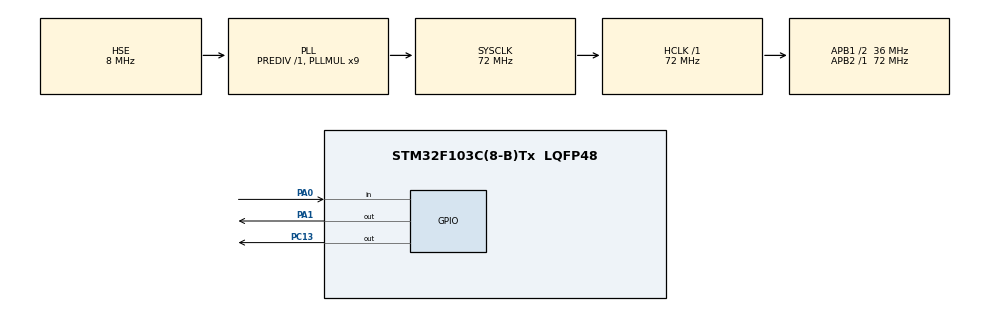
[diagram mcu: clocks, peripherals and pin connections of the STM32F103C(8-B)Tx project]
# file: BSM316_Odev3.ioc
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Mcu.Family=STM32F1
Mcu.Name=STM32F103C(8-B)Tx
Mcu.Package=LQFP48
NVIC.PriorityGroup=NVIC_PRIORITYGROUP_4
NVIC.TIM2_IRQn=true\:0\:0\:false\:false\:true\:true\:true\:true
PA0-WKUP.GPIO_PuPd=GPIO_PULLUP
PA0-WKUP.Signal=GPIO_Input
PA1.Signal=GPIO_Output
PA13.Mode=Serial_Wire
PA13.Signal=SYS_JTMS-SWDIO
PA14.Mode=Serial_Wire
PA14.Signal=SYS_JTCK-SWCLK
PC13-TAMPER-RTC.Signal=GPIO_Output
PD0-OSC_IN.Mode=HSE-External-Oscillator
PD0-OSC_IN.Signal=RCC_OSC_IN
PD1-OSC_OUT.Mode=HSE-External-Oscillator
PD1-OSC_OUT.Signal=RCC_OSC_OUT
ProjectManager.HeapSize=0x200
ProjectManager.StackSize=0x400
ProjectManager.TargetToolchain=Makefile
RCC.AHBFreq_Value=72000000
RCC.APB1CLKDivider=RCC_HCLK_DIV2
RCC.APB1Freq_Value=36000000
RCC.APB1TimFreq_Value=72000000
RCC.APB2Freq_Value=72000000
RCC.APB2TimFreq_Value=72000000
RCC.HCLKFreq_Value=72000000
RCC.PLLMUL=RCC_PLL_MUL9
RCC.PLLSourceVirtual=RCC_PLLSOURCE_HSE
RCC.SYSCLKFreq_VALUE=72000000
RCC.SYSCLKSource=RCC_SYSCLKSOURCE_PLLCLK
RCC.USBFreq_Value=72000000
TIM2.Period=9999
TIM2.Prescaler=7199
VP_TIM2_VS_ClockSourceINT.Mode=Internal
board=custom

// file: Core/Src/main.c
/* USER CODE BEGIN Header */
/**
  ******************************************************************************
  * @file           : main.c
  * @brief          : Main program body
  ******************************************************************************
  * @attention
  *
  * Copyright (c) 2026 STMicroelectronics.
  * All rights reserved.
  *
  * This software is licensed under terms that can be found in the LICENSE file
  * in the root directory of this software component.
  * If no LICENSE file comes with this software, it is provided AS-IS.
  *
  ******************************************************************************
  */
/* USER CODE END Header */
#include "main.h"

TIM_HandleTypeDef htim2;

void SystemClock_Config(void);
static void MX_GPIO_Init(void);
static void MX_TIM2_Init(void);

/* USER CODE BEGIN 0 */
#define FLASH_USER_ADDR 0x0800FC00 // STM32F103C8T6 için 63. sayfa başlangıç adresi

uint32_t blink_count = 4;
uint32_t current_blink = 0;
uint8_t is_waiting = 0;
uint8_t wait_seconds = 0;
uint8_t led_state = 0; // 0: Sönük, 1: Yanıyor

void Save_Blink_Count_To_Flash(uint16_t data) {
    HAL_FLASH_Unlock();

    FLASH_EraseInitTypeDef eraseConfig;
    uint32_t PageError = 0;
    eraseConfig.TypeErase = FLASH_TYPEERASE_PAGES;
    eraseConfig.PageAddress = FLASH_USER_ADDR;
    eraseConfig.NbPages = 1;

    HAL_FLASHEx_Erase(&eraseConfig, &PageError); // Sayfayı sil
    HAL_FLASH_Program(FLASH_TYPEPROGRAM_HALFWORD, FLASH_USER_ADDR, data); // Yeni değeri yaz

    HAL_FLASH_Lock();
}

uint16_t Read_Blink_Count_From_Flash(void) {
    return *(__IO uint16_t *)FLASH_USER_ADDR; // Belirtilen adresten değeri oku
}

/* USER CODE END 0 */

int main(void)
{

  /* MCU Configuration--------------------------------------------------------*/

  /* Reset of all peripherals, Initializes the Flash interface and the Systick. */
  HAL_Init();

  /* Configure the system clock */
  SystemClock_Config();

  /* Initialize all configured peripherals */
  MX_GPIO_Init();
  MX_TIM2_Init();
  /* USER CODE BEGIN 2 */

  HAL_GPIO_WritePin(GPIOA, GPIO_PIN_1, GPIO_PIN_RESET); // PA1 sürekli lojik 0 olarak ayarlandı
  HAL_GPIO_WritePin(GPIOC, GPIO_PIN_13, GPIO_PIN_SET); // LED başlangıçta sönük

  uint16_t read_val = Read_Blink_Count_From_Flash();

  // Flash boş ise (0xFFFF) veya değer 7'den büyükse
  if (read_val > 7 || read_val < 4) {
      blink_count = 4;
      Save_Blink_Count_To_Flash((uint16_t)blink_count);
  } else {
      blink_count = read_val; // Değer geçerliyse flash'tan yükle
  }

  HAL_TIM_Base_Start_IT(&htim2); // TIM2 kesmelerini başlat
  /* USER CODE END 2 */

  /* Infinite loop */
  while (1)
  {

    /* USER CODE BEGIN 3 */

    static uint32_t btn_press_time = 0;
  static uint8_t btn_state = 0; // 0: Basılmadı, 1: Basıldı, 2: Uzun basıldı (bekleme)

  // PA0'ın düşük olması (lojik 0), butonun basıldığını (veya PA0 ile PA1'in kısa devre edildiğini) gösterir
  if (HAL_GPIO_ReadPin(GPIOA, GPIO_PIN_0) == GPIO_PIN_RESET) {
      if (btn_state == 0) {
          btn_state = 1;
          btn_press_time = HAL_GetTick(); // Basım anını kaydet
      } else if (btn_state == 1) {
          // Eğer 3 saniyeden (3000 ms) fazla basılı tutulduysa
          if (HAL_GetTick() - btn_press_time >= 3000) {
              blink_count = 4; // Fabrika ayarlarına dön
              Save_Blink_Count_To_Flash((uint16_t)blink_count); // Flash'ı güncelle

              // Animasyonu sıfırla ki kullanıcı değişikliği hemen görsün
              is_waiting = 0;
              wait_seconds = 0;
              current_blink = 0;
              HAL_GPIO_WritePin(GPIOC, GPIO_PIN_13, GPIO_PIN_SET);
              led_state = 0;

              btn_state = 2; // Buton bırakılana kadar bu durumda bekle
          }
      }
  } else { // Buton Bırakıldı
      if (btn_state == 1) { // Kısa basım
          if (HAL_GetTick() - btn_press_time > 50) { // 50ms Debounce filtresi
              blink_count++;
              if (blink_count > 7) {
                  blink_count = 4; // 7 iken basılırsa 4 yap
              }
              Save_Blink_Count_To_Flash((uint16_t)blink_count); // Flash'a yaz

              // Animasyonu sıfırla
              is_waiting = 0;
              wait_seconds = 0;
              current_blink = 0;
              HAL_GPIO_WritePin(GPIOC, GPIO_PIN_13, GPIO_PIN_SET);
              led_state = 0;
          }
      }
      btn_state = 0; // Durumu sıfırla
  }

  }
  /* USER CODE END 3 */
}

void SystemClock_Config(void)
{
  RCC_OscInitTypeDef RCC_OscInitStruct = {0};
  RCC_ClkInitTypeDef RCC_ClkInitStruct = {0};

  /** Initializes the RCC Oscillators according to the specified parameters
  * in the RCC_OscInitTypeDef structure.
  */
  RCC_OscInitStruct.OscillatorType = RCC_OSCILLATORTYPE_HSE;
  RCC_OscInitStruct.HSEState = RCC_HSE_ON;
  RCC_OscInitStruct.HSEPredivValue = RCC_HSE_PREDIV_DIV1;
  RCC_OscInitStruct.HSIState = RCC_HSI_ON;
  RCC_OscInitStruct.PLL.PLLState = RCC_PLL_ON;
  RCC_OscInitStruct.PLL.PLLSource = RCC_PLLSOURCE_HSE;
  RCC_OscInitStruct.PLL.PLLMUL = RCC_PLL_MUL9;
  if (HAL_RCC_OscConfig(&RCC_OscInitStruct) != HAL_OK)
  {
    Error_Handler();
  }

  /** Initializes the CPU, AHB and APB buses clocks
  */
  RCC_ClkInitStruct.ClockType = RCC_CLOCKTYPE_HCLK|RCC_CLOCKTYPE_SYSCLK
                              |RCC_CLOCKTYPE_PCLK1|RCC_CLOCKTYPE_PCLK2;
  RCC_ClkInitStruct.SYSCLKSource = RCC_SYSCLKSOURCE_PLLCLK;
  RCC_ClkInitStruct.AHBCLKDivider = RCC_SYSCLK_DIV1;
  RCC_ClkInitStruct.APB1CLKDivider = RCC_HCLK_DIV2;
  RCC_ClkInitStruct.APB2CLKDivider = RCC_HCLK_DIV1;

  if (HAL_RCC_ClockConfig(&RCC_ClkInitStruct, FLASH_LATENCY_2) != HAL_OK)
  {
    Error_Handler();
  }
}

static void MX_TIM2_Init(void)
{

  TIM_ClockConfigTypeDef sClockSourceConfig = {0};
  TIM_MasterConfigTypeDef sMasterConfig = {0};

  htim2.Instance = TIM2;
  htim2.Init.Prescaler = 7199;
  htim2.Init.CounterMode = TIM_COUNTERMODE_UP;
  htim2.Init.Period = 9999;
  htim2.Init.ClockDivision = TIM_CLOCKDIVISION_DIV1;
  htim2.Init.AutoReloadPreload = TIM_AUTORELOAD_PRELOAD_DISABLE;
  if (HAL_TIM_Base_Init(&htim2) != HAL_OK)
  {
    Error_Handler();
  }
  sClockSourceConfig.ClockSource = TIM_CLOCKSOURCE_INTERNAL;
  if (HAL_TIM_ConfigClockSource(&htim2, &sClockSourceConfig) != HAL_OK)
  {
    Error_Handler();
  }
  sMasterConfig.MasterOutputTrigger = TIM_TRGO_RESET;
  sMasterConfig.MasterSlaveMode = TIM_MASTERSLAVEMODE_DISABLE;
  if (HAL_TIMEx_MasterConfigSynchronization(&htim2, &sMasterConfig) != HAL_OK)
  {
    Error_Handler();
  }

}

static void MX_GPIO_Init(void)
{
  GPIO_InitTypeDef GPIO_InitStruct = {0};

  /* GPIO Ports Clock Enable */
  __HAL_RCC_GPIOC_CLK_ENABLE();
  __HAL_RCC_GPIOD_CLK_ENABLE();
  __HAL_RCC_GPIOA_CLK_ENABLE();

  /*Configure GPIO pin Output Level */
  HAL_GPIO_WritePin(GPIOC, GPIO_PIN_13, GPIO_PIN_RESET);

  /*Configure GPIO pin Output Level */
  HAL_GPIO_WritePin(GPIOA, GPIO_PIN_1, GPIO_PIN_RESET);

  /*Configure GPIO pin : PC13 */
  GPIO_InitStruct.Pin = GPIO_PIN_13;
  GPIO_InitStruct.Mode = GPIO_MODE_OUTPUT_PP;
  GPIO_InitStruct.Pull = GPIO_NOPULL;
  GPIO_InitStruct.Speed = GPIO_SPEED_FREQ_LOW;
  HAL_GPIO_Init(GPIOC, &GPIO_InitStruct);

  /*Configure GPIO pin : PA0 */
  GPIO_InitStruct.Pin = GPIO_PIN_0;
  GPIO_InitStruct.Mode = GPIO_MODE_INPUT;
  GPIO_InitStruct.Pull = GPIO_PULLUP;
  HAL_GPIO_Init(GPIOA, &GPIO_InitStruct);

  /*Configure GPIO pin : PA1 */
  GPIO_InitStruct.Pin = GPIO_PIN_1;
  GPIO_InitStruct.Mode = GPIO_MODE_OUTPUT_PP;
  GPIO_InitStruct.Pull = GPIO_NOPULL;
  GPIO_InitStruct.Speed = GPIO_SPEED_FREQ_LOW;
  HAL_GPIO_Init(GPIOA, &GPIO_InitStruct);

}

/* USER CODE BEGIN 4 */
// TIM2 adlı zamanlayıcı saniyede 1 kere interrupt oluşturur
void HAL_TIM_PeriodElapsedCallback(TIM_HandleTypeDef *htim) {
    if (htim->Instance == TIM2) {
        if (is_waiting) {
            wait_seconds++;
            if (wait_seconds >= 5) { // 5 saniye bekleme durumu
                is_waiting = 0;
                wait_seconds = 0;
                current_blink = 0;
            }
        } else {
            if (led_state == 0) {
                // LED'i yak (Bluepill'de PC13 genellikle Lojik 0 ile yanar)
                HAL_GPIO_WritePin(GPIOC, GPIO_PIN_13, GPIO_PIN_RESET);
                led_state = 1;
            } else {
                // LED'i söndür
                HAL_GPIO_WritePin(GPIOC, GPIO_PIN_13, GPIO_PIN_SET);
                led_state = 0;
                current_blink++; // Bir yanıp sönme döngüsü tamamlandı

                if (current_blink >= blink_count) {
                    is_waiting = 1; // İstenen sayıya ulaşıldı, bekleme durumuna geç
                }
            }
        }
    }
}

/* USER CODE END 4 */

void Error_Handler(void)
{
  __disable_irq();
  while (1)
  {
  }
}
